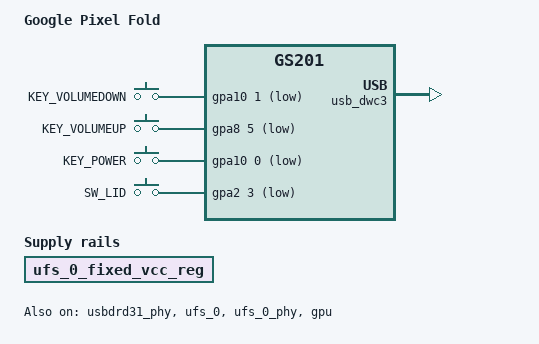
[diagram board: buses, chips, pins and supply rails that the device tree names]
// SPDX-License-Identifier: GPL-2.0-only
/*
 * Google Pixel Fold (felix).
 *
 * Same GS201 silicon as the Pixel 7 Pro. This board file brings up USB,
 * the cover framebuffer the bootloader is already scanning, UFS, the
 * GPU, the volume keys, the hinge hall sensor, and the cover touch
 * rails on the main PMIC. It does not describe either panel or either
 * touch controller. The inner panel has no node that could drive it.
 */

/dts-v1/;

#include <dt-bindings/input/input.h>
#include "gs201.dtsi"

/ {
	model = "Google Pixel Fold";
	compatible = "google,gs201-felix", "google,gs201";

	/*
	 * ABL matches (product id 0x09855000 | major rev). This phone is
	 * GS201 MP1.0, package mode 0, SoC rev 2: the same B0 id as cheetah.
	 * The image packer appends a second DTB with 0x09855000.
	 */
	soc_id = <0x09855001 0x0>;

	chosen {
		/*
		 * ABL requires bootargs and appends its own, including
		 * console=null. Nothing here writes a display register. The
		 * framebuffer below is the cover plane read from DPP2 on the
		 * first boot (1080x2092 at 0xfc000000). The inner plane, DPP0
		 * at 0xfac00000, is not described.
		 */
		bootargs = "console=tty0 panic=10 clk_ignore_unused pd_ignore_unused rdinit=/init";
		#address-cells = <2>;
		#size-cells = <1>;
		ranges;

		framebuffer0: framebuffer@fc000000 {
			compatible = "simple-framebuffer";
			memory-region = <&cont_splash_mem>;
			width = <1080>;
			height = <2092>;
			stride = <(1080 * 4)>;
			format = "a8r8g8b8";
		};
	};

	reserved-memory {
		#address-cells = <2>;
		#size-cells = <1>;
		ranges;

		/*
		 * The inner plane at 0xfac00000 is left unreserved. DECON0's
		 * trigger stays masked.
		 */
		cont_splash_mem: splash@fc000000 {
			reg = <0x0 0xfc000000 (1080 * 2092 * 4)>;
			no-map;
		};
	};

	/*
	 * UFS VCC. The bootloader leaves this rail on. There is no gs201
	 * GPIO driver yet, so describe it as an always-on fixed regulator,
	 * as on the Pixel 7 Pro.
	 */
	ufs_0_fixed_vcc_reg: regulator-ufs-vcc {
		compatible = "regulator-fixed";
		regulator-name = "ufs-vcc";
		regulator-always-on;
		regulator-boot-on;
	};

	/*
	 * Volume down is gpa10-1 with a pull-up. Volume up is gpa8-5 with
	 * no pull. Power is gpa10-0, the S2MPG12 PWRONB line, with a
	 * pull-up. The hinge hall is the factory hall_sensor on gpa2-3,
	 * active-low with no pull. All four are active-low. The PMIC's
	 * own long-press reset is unaffected.
	 */
	gpio-keys {
		compatible = "gpio-keys";
		pinctrl-names = "default";
		pinctrl-0 = <&key_voldown>, <&key_volup>, <&key_power>, <&hall_lid>;

		button-vol-down {
			label = "KEY_VOLUMEDOWN";
			linux,code = <KEY_VOLUMEDOWN>;
			gpios = <&gpa10 1 GPIO_ACTIVE_LOW>;
			wakeup-source;
		};

		button-vol-up {
			label = "KEY_VOLUMEUP";
			linux,code = <KEY_VOLUMEUP>;
			gpios = <&gpa8 5 GPIO_ACTIVE_LOW>;
			wakeup-source;
		};

		button-power {
			label = "KEY_POWER";
			linux,code = <KEY_POWER>;
			gpios = <&gpa10 0 GPIO_ACTIVE_LOW>;
			wakeup-source;
		};

		switch-lid {
			label = "SW_LID";
			linux,input-type = <EV_SW>;
			linux,code = <SW_LID>;
			gpios = <&gpa2 3 GPIO_ACTIVE_LOW>;
			linux,can-disable;
			wakeup-source;
		};
	};
};

&usbdrd31_phy {
	status = "okay";
};

&usb_dwc3 {
	status = "okay";
};

&ufs_0 {
	vcc-supply = <&ufs_0_fixed_vcc_reg>;
	status = "okay";
};

&ufs_0_phy {
	status = "okay";
};

&gpu {
	/* No mali-supply: the G3D rails follow the PMU power domain and ACPM. */
	status = "okay";
};

&pinctrl_gpio_alive {
	hall_lid: hall-lid-pins {
		samsung,pins = "gpa2-3";
		samsung,pin-function = <GS101_PIN_FUNC_EINT>;
		samsung,pin-pud = <GS101_PIN_PULL_NONE>;
	};
};

&acpm_ipc {
	/*
	 * Main PMIC, cover touch rails only. LDO25M is L25M_OUTER_TS_DVDD,
	 * fixed at 1.8 V, and LDO26M is L26M_OUTER_TS_AVDD, fixed at 3.3 V.
	 * Nothing else on the stock board consumes them. The sub-PMIC is
	 * not described.
	 */
	pmic-1 {
		compatible = "samsung,s2mpg12-pmic";
		interrupts = <GIC_SPI 72 IRQ_TYPE_LEVEL_HIGH>;
		google,vgpio2ap-sysreg = <&sysreg_vgpio2ap>;
		wakeup-source;
		status = "disabled";

		regulators {
			ldo25m: ldo25m {
				regulator-name = "vdd-outer-ts";
				regulator-min-microvolt = <1800000>;
				regulator-max-microvolt = <1800000>;
			};

			ldo26m: ldo26m {
				regulator-name = "avdd-outer-ts";
				regulator-min-microvolt = <3300000>;
				regulator-max-microvolt = <3300000>;
			};
		};
	};
};
